# PER1_AP register map
Vendor: Texas Instruments
Peripheral module from a debugger description file (folder DRA74xP_75xP_76xP_77xP).
Registers are 32-bit, read-only, reset 0x0 unless marked. A register's access mark holds for its fields unless they carry their own. Offsets are as the file gives them; lines under a group give offsets from that group; [hi:lo] are bit positions; {n}, {i} and the like mark numbered series; 'fields as' and 'values as' point back to an identical list; <NAME> marks a mode.

## PER1_AP
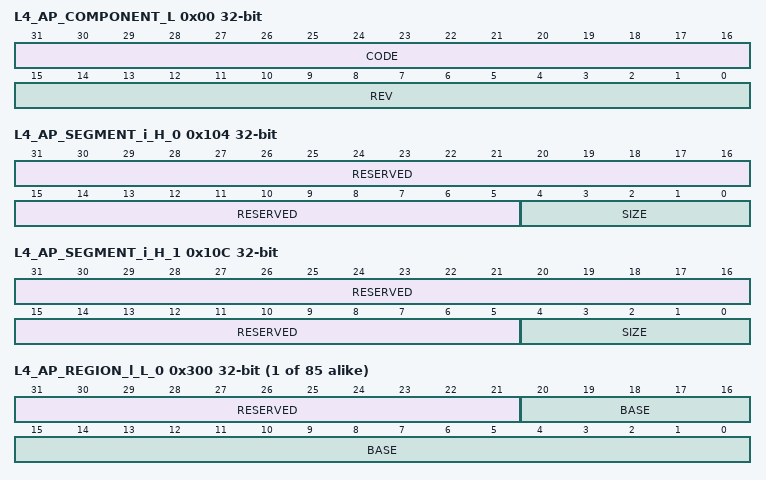
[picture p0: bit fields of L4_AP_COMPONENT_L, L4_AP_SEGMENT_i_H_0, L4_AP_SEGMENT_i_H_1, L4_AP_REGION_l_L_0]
0x00 L4_AP_COMPONENT_L reset not defined — Contains a component code and revision, which are used to identify the hardware of the component.
  [31:16] CODE — Interconnect code
  [15:0] REV — Component revision code
0x04 L4_AP_COMPONENT_H — Contains a component code and revision, which are used to identify the hardware of the component.
  [31:0] RESERVED — Read returns 0
0x100 L4_AP_SEGMENT_i_L_0 reset not defined — Define the base address of each segments
  [31:0] BASE — The base address of the segment (with 0s from bit 0 to bit SIZE-1).
0x104 L4_AP_SEGMENT_i_H_0 (reset mask 0xFFFFFFE0) — Define the size of each segments
  [31:5] RESERVED — Read returns 0.
  [4:0] SIZE — Segment size is a power of 2, where 2 is the byte size of a segment (all segment registers use the same size).
0x108 L4_AP_SEGMENT_i_L_1 reset not defined — Define the base address of each segments
  fields as L4_AP_SEGMENT_i_L_0
0x10C L4_AP_SEGMENT_i_H_1 (reset mask 0xFFFFFFE0) — Define the size of each segments
  fields as L4_AP_SEGMENT_i_H_0
{0x200+8i} L4_AP_PROT_GROUP_MEMBERS_k_L_{i} reset 0xFFFF (i=0..7) — Define ConnID bit vectors for a protection group.
  [15:0] CONNID_BIT_VECTOR — Specifies protection group members N is 2**W, where W is the connID width
{0x204+8i} L4_AP_PROT_GROUP_MEMBERS_k_H_{i} (i=0..7) — Define ConnID bit vectors for a protection group.
  [31:0] RESERVED — Read returns 0's
{0x280+8i} L4_AP_PROT_GROUP_ROLES_k_L_{i} reset 0xFFFF (i=0..7) — Define MReqInfo bit vectors for a protection group.
  [31:0] ENABLE — Enabled bits N is 2**W, where W (W is less than or equal to 6) is the number of MReqInfo bits configured for role checking
{0x284+8i} L4_AP_PROT_GROUP_ROLES_k_H_{i} reset 0xFFFF (i=0..7) — Define ConnID bit vectors for a protection group.
  [31:0] ENABLE — Enabled bits N is 2**W, where W (W is less than or equal to 6) is the number of MReqInfo bits configured for role checking.
{0x300+8i} L4_AP_REGION_l_L_{i} (reset mask 0xFFE00000) (i=0..84) — Define the base address of the region in respect to the segment it belongs to.
  [31:21] RESERVED — Read returns 0.
  [20:0] BASE — Sets the base address of the region relative to its segment base.
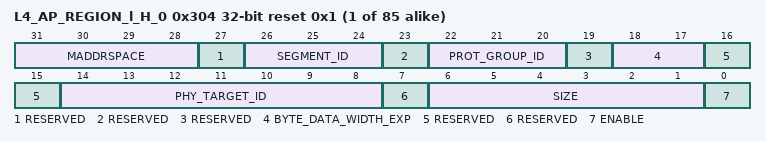
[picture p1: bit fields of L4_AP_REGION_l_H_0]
{0x304+8i} L4_AP_REGION_l_H_{i} access per field reset 0x1 (reset mask 0x8898081) (i=0..84) — Define the size, protection group and segment ID of the region
  [31:28] MADDRSPACE ro — Target interconnect MAddrSpace
  [27] RESERVED ro — Read returns 0
  [26:24] SEGMENT_ID ro — Segment ID of the region
  [23] RESERVED ro — Read returns 0
  [22:20] PROT_GROUP_ID rw — Protection group ID
  [19] RESERVED ro — Read returns 0
  [18:17] BYTE_DATA_WIDTH_EXP ro — Target data byte width
  [16:15] RESERVED ro — Read returns 0
  [14:8] PHY_TARGET_ID ro — Physical target ID
  [7] RESERVED ro — Read returns 0.
  [6:1] SIZE ro — Define the size of the region in bytes. 2 equals the region.
  [0] ENABLE ro — 0x0: Disable the region, no access allows 0x1: Enable the region, with access as define in registers
